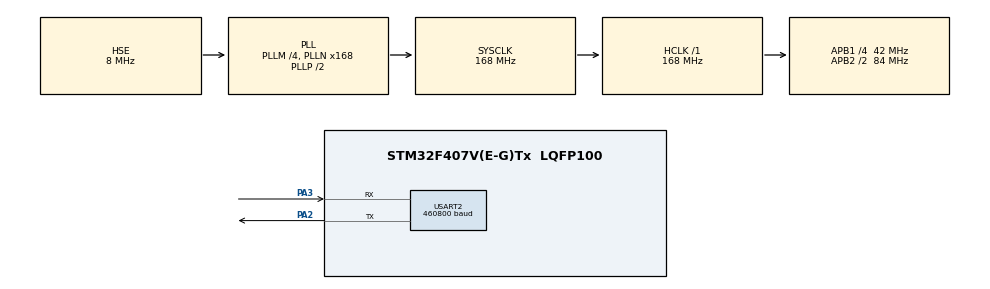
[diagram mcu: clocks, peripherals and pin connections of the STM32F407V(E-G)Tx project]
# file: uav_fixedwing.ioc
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Dma.Request0=USART2_RX
Dma.Request1=USART2_TX
Dma.USART2_RX.0.Direction=DMA_PERIPH_TO_MEMORY
Dma.USART2_RX.0.FIFOMode=DMA_FIFOMODE_DISABLE
Dma.USART2_RX.0.Instance=DMA1_Stream5
Dma.USART2_RX.0.MemDataAlignment=DMA_MDATAALIGN_BYTE
Dma.USART2_RX.0.MemInc=DMA_MINC_ENABLE
Dma.USART2_RX.0.Mode=DMA_NORMAL
Dma.USART2_RX.0.PeriphDataAlignment=DMA_PDATAALIGN_BYTE
Dma.USART2_RX.0.PeriphInc=DMA_PINC_DISABLE
Dma.USART2_RX.0.Priority=DMA_PRIORITY_LOW
Dma.USART2_TX.1.Direction=DMA_MEMORY_TO_PERIPH
Dma.USART2_TX.1.FIFOMode=DMA_FIFOMODE_DISABLE
Dma.USART2_TX.1.Instance=DMA1_Stream6
Dma.USART2_TX.1.MemDataAlignment=DMA_MDATAALIGN_BYTE
Dma.USART2_TX.1.MemInc=DMA_MINC_ENABLE
Dma.USART2_TX.1.Mode=DMA_NORMAL
Dma.USART2_TX.1.PeriphDataAlignment=DMA_PDATAALIGN_BYTE
Dma.USART2_TX.1.PeriphInc=DMA_PINC_DISABLE
Dma.USART2_TX.1.Priority=DMA_PRIORITY_LOW
FREERTOS.Mutexes01=system_io_mutex,Dynamic,NULL,Available
FREERTOS.Tasks01=autopilot_task,40,1024,start_autopilot_task,Default,NULL,Dynamic,NULL,NULL;rx_task,24,1024,start_rx_task,Default,NULL,Dynamic,NULL,NULL
Mcu.Family=STM32F4
Mcu.Name=STM32F407V(E-G)Tx
Mcu.Package=LQFP100
NVIC.DMA1_Stream5_IRQn=true\:5\:0\:false\:false\:true\:true\:false\:true\:true
NVIC.DMA1_Stream6_IRQn=true\:5\:0\:false\:false\:true\:true\:false\:true\:true
NVIC.PriorityGroup=NVIC_PRIORITYGROUP_4
NVIC.TIM1_UP_TIM10_IRQn=true\:15\:0\:false\:false\:true\:false\:false\:true\:true
NVIC.TIM3_IRQn=true\:5\:0\:false\:false\:true\:true\:true\:true\:true
NVIC.TimeBase=TIM1_UP_TIM10_IRQn
NVIC.TimeBaseIP=TIM1
NVIC.USART2_IRQn=true\:5\:0\:false\:false\:true\:true\:false\:true\:true
PA13.Mode=Serial_Wire
PA13.Signal=SYS_JTMS-SWDIO
PA14.Mode=Serial_Wire
PA14.Signal=SYS_JTCK-SWCLK
PA2.Mode=Asynchronous
PA2.Signal=USART2_TX
PA3.Mode=Asynchronous
PA3.Signal=USART2_RX
PH0-OSC_IN.Mode=HSE-External-Oscillator
PH0-OSC_IN.Signal=RCC_OSC_IN
PH1-OSC_OUT.Mode=HSE-External-Oscillator
PH1-OSC_OUT.Signal=RCC_OSC_OUT
ProjectManager.HeapSize=0x200
ProjectManager.StackSize=0x400
ProjectManager.TargetToolchain=CMake
RCC.48MHZClocksFreq_Value=84000000
RCC.AHBFreq_Value=168000000
RCC.APB1CLKDivider=RCC_HCLK_DIV4
RCC.APB1Freq_Value=42000000
RCC.APB1TimFreq_Value=84000000
RCC.APB2CLKDivider=RCC_HCLK_DIV2
RCC.APB2Freq_Value=84000000
RCC.APB2TimFreq_Value=168000000
RCC.CortexFreq_Value=168000000
RCC.HCLKFreq_Value=168000000
RCC.HSE_VALUE=8000000
RCC.HSI_VALUE=16000000
RCC.LSE_VALUE=32768
RCC.PLLM=4
RCC.PLLN=168
RCC.PLLSourceVirtual=RCC_PLLSOURCE_HSE
RCC.SYSCLKFreq_VALUE=168000000
RCC.SYSCLKSource=RCC_SYSCLKSOURCE_PLLCLK
RCC.VCOOutputFreq_Value=336000000
TIM3.Period=100-1
TIM3.Prescaler=8400-1
USART2.BaudRate=460800
USART2.VirtualMode=VM_ASYNC
VP_FREERTOS_VS_CMSIS_V2.Mode=CMSIS_V2
VP_SYS_VS_tim1.Mode=TIM1
VP_TIM3_VS_ClockSourceINT.Mode=Internal
board=custom

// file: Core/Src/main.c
/* USER CODE BEGIN Header */
/**
  ******************************************************************************
  * @file           : main.c
  * @brief          : Main program body
  ******************************************************************************
  * @attention
  *
  * Copyright (c) 2026 STMicroelectronics.
  * All rights reserved.
  *
  * This software is licensed under terms that can be found in the LICENSE file
  * in the root directory of this software component.
  * If no LICENSE file comes with this software, it is provided AS-IS.
  *
  ******************************************************************************
  */
/* USER CODE END Header */
#include "main.h"
#include "cmsis_os.h"
#include "dma.h"
#include "tim.h"
#include "usart.h"
#include "gpio.h"

/* USER CODE BEGIN Includes */
#include "System/init.h"
/* USER CODE END Includes */

void SystemClock_Config(void);
void MX_FREERTOS_Init(void);

int main(void)
{

  /* MCU Configuration--------------------------------------------------------*/

  /* Reset of all peripherals, Initializes the Flash interface and the Systick. */
  HAL_Init();

  /* Configure the system clock */
  SystemClock_Config();

  /* Initialize all configured peripherals */
  MX_GPIO_Init();
  MX_DMA_Init();
  MX_USART2_UART_Init();
  MX_TIM3_Init();
  /* USER CODE BEGIN 2 */
  user_system_init();
  /* USER CODE END 2 */

  /* Init scheduler */
  osKernelInitialize();  /* Call init function for freertos objects (in cmsis_os2.c) */
  MX_FREERTOS_Init();

  /* Start scheduler */
  osKernelStart();

  /* We should never get here as control is now taken by the scheduler */

  /* Infinite loop */
  while (1)
  {

  }
}

void SystemClock_Config(void)
{
  RCC_OscInitTypeDef RCC_OscInitStruct = {0};
  RCC_ClkInitTypeDef RCC_ClkInitStruct = {0};

  /** Configure the main internal regulator output voltage
  */
  __HAL_RCC_PWR_CLK_ENABLE();
  __HAL_PWR_VOLTAGESCALING_CONFIG(PWR_REGULATOR_VOLTAGE_SCALE1);

  /** Initializes the RCC Oscillators according to the specified parameters
  * in the RCC_OscInitTypeDef structure.
  */
  RCC_OscInitStruct.OscillatorType = RCC_OSCILLATORTYPE_HSE;
  RCC_OscInitStruct.HSEState = RCC_HSE_ON;
  RCC_OscInitStruct.PLL.PLLState = RCC_PLL_ON;
  RCC_OscInitStruct.PLL.PLLSource = RCC_PLLSOURCE_HSE;
  RCC_OscInitStruct.PLL.PLLM = 4;
  RCC_OscInitStruct.PLL.PLLN = 168;
  RCC_OscInitStruct.PLL.PLLP = RCC_PLLP_DIV2;
  RCC_OscInitStruct.PLL.PLLQ = 4;
  if (HAL_RCC_OscConfig(&RCC_OscInitStruct) != HAL_OK)
  {
    Error_Handler();
  }

  /** Initializes the CPU, AHB and APB buses clocks
  */
  RCC_ClkInitStruct.ClockType = RCC_CLOCKTYPE_HCLK|RCC_CLOCKTYPE_SYSCLK
                              |RCC_CLOCKTYPE_PCLK1|RCC_CLOCKTYPE_PCLK2;
  RCC_ClkInitStruct.SYSCLKSource = RCC_SYSCLKSOURCE_PLLCLK;
  RCC_ClkInitStruct.AHBCLKDivider = RCC_SYSCLK_DIV1;
  RCC_ClkInitStruct.APB1CLKDivider = RCC_HCLK_DIV4;
  RCC_ClkInitStruct.APB2CLKDivider = RCC_HCLK_DIV2;

  if (HAL_RCC_ClockConfig(&RCC_ClkInitStruct, FLASH_LATENCY_5) != HAL_OK)
  {
    Error_Handler();
  }
}

void HAL_TIM_PeriodElapsedCallback(TIM_HandleTypeDef *htim)
{
  if (htim->Instance == TIM1)
  {
    HAL_IncTick();
  }
}

void Error_Handler(void)
{
  __disable_irq();
  while (1)
  {
  }
}

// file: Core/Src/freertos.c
/* USER CODE BEGIN Header */
/**
  ******************************************************************************
  * File Name          : freertos.c
  * Description        : Code for freertos applications
  ******************************************************************************
  * @attention
  *
  * Copyright (c) 2026 STMicroelectronics.
  * All rights reserved.
  *
  * This software is licensed under terms that can be found in the LICENSE file
  * in the root directory of this software component.
  * If no LICENSE file comes with this software, it is provided AS-IS.
  *
  ******************************************************************************
  */
/* USER CODE END Header */

#include "FreeRTOS.h"
#include "task.h"
#include "main.h"
#include "cmsis_os.h"

/* USER CODE BEGIN Includes */
#include "FreeRTOS/tasks.h"
/* USER CODE END Includes */

/* Definitions for autopilot_task */
osThreadId_t autopilot_taskHandle;
const osThreadAttr_t autopilot_task_attributes = {
  .name = "autopilot_task",
  .stack_size = 1024 * 4,
  .priority = (osPriority_t) osPriorityHigh,
};
/* Definitions for rx_task */
osThreadId_t rx_taskHandle;
const osThreadAttr_t rx_task_attributes = {
  .name = "rx_task",
  .stack_size = 1024 * 4,
  .priority = (osPriority_t) osPriorityNormal,
};
/* Definitions for system_io_mutex */
osMutexId_t system_io_mutexHandle;
const osMutexAttr_t system_io_mutex_attributes = {
  .name = "system_io_mutex"
};

void start_autopilot_task(void *argument);
void start_rx_task(void *argument);

void MX_FREERTOS_Init(void); /* (MISRA C 2004 rule 8.1) */

void MX_FREERTOS_Init(void) {
  /* Create the mutex(es) */
  /* creation of system_io_mutex */
  system_io_mutexHandle = osMutexNew(&system_io_mutex_attributes);

  /* Create the thread(s) */
  /* creation of autopilot_task */
  autopilot_taskHandle = osThreadNew(start_autopilot_task, NULL, &autopilot_task_attributes);

  /* creation of rx_task */
  rx_taskHandle = osThreadNew(start_rx_task, NULL, &rx_task_attributes);

}

void start_autopilot_task(void *argument)
{
  /* USER CODE BEGIN start_autopilot_task */
  /* Infinite loop */
  autopilot_task(argument);
  /* USER CODE END start_autopilot_task */
}

void start_rx_task(void *argument)
{
  /* USER CODE BEGIN start_rx_task */
  /* Infinite loop */
  rx_task(argument);
  /* USER CODE END start_rx_task */
}
